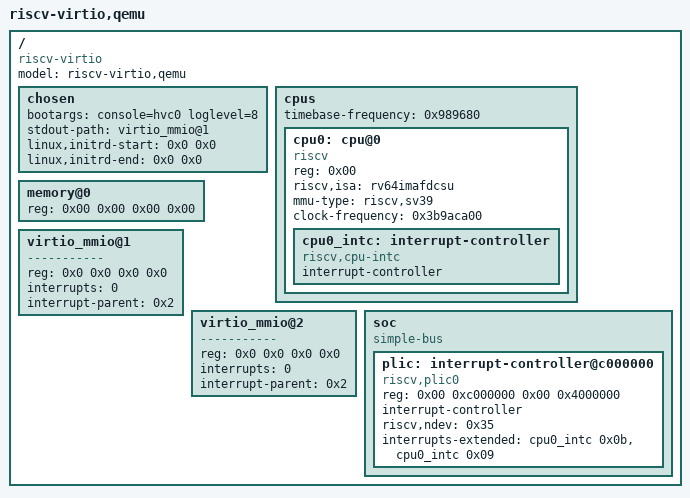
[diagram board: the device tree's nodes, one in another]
/dts-v1/;

/ {
    #address-cells = <0x02>;
    #size-cells = <0x02>;
    compatible = "riscv-virtio";
    model = "riscv-virtio,qemu";

    chosen {
		bootargs = "console=hvc0 loglevel=8";
		stdout-path = "virtio_mmio@1";
		linux,initrd-start = <0x0 0x0>;
        linux,initrd-end = <0x0 0x0>;
    };

    cpus {
        #address-cells = <0x01>;
        #size-cells = <0x00>;
        timebase-frequency = <0x989680>;

        cpu0: cpu@0 {
            device_type = "cpu";
            reg = <0x00>;
            status = "okay";
            compatible = "riscv";
            riscv,isa = "rv64imafdcsu";
            mmu-type = "riscv,sv39";
            clock-frequency = <0x3b9aca00>;

            cpu0_intc: interrupt-controller {
                #interrupt-cells = <0x01>;
                interrupt-controller;
                compatible = "riscv,cpu-intc";
                phandle = <0x01>;
            };
        };
    };

    memory@0 {
        device_type = "memory";
        reg = <0x00 0x00 0x00 0x00>;
    };

	virtio_mmio@1 {
		compatible = "-----------";
		reg = <0x0 0x0 0x0 0x0>;
		interrupts = <0>;
		interrupt-parent = <0x2>;
	};

	virtio_mmio@2 {
		compatible = "-----------";
		reg = <0x0 0x0 0x0 0x0>;
		interrupts = <0>;
		interrupt-parent = <0x2>;
	};

    soc {
        #address-cells = <0x02>;
        #size-cells = <0x02>;
        compatible = "simple-bus";
        ranges;

        plic: interrupt-controller@c000000 {
            compatible = "riscv,plic0";
            reg = <0x00 0xc000000 0x00 0x4000000>;
            interrupt-controller;
            #interrupt-cells = <0x01>;
            riscv,ndev = <0x35>;
            interrupts-extended = <&cpu0_intc 0x0b &cpu0_intc 0x09>;
            phandle = <0x02>; 
        };
    };
};
